# ADuCM320i register map
Vendor: Analog Devices Inc.; Series: ARMCM3; File version: 1.0
CPU: CM3 r2p1, little endian, no MPU, no FPU, 3 interrupt priority bits
Registers are 16-bit, read-write, no defined reset value unless marked. A register's access mark holds for its fields unless they carry their own. Offsets are from the block's base; [hi:lo] are bit positions.

## Timer1 — General purpose timer 1
Base 0x40000400
0x00 T1LD — 16-bit load value register
  [15:0] LOAD range 0x00000000..0x0000FFFF — Load value
0x04 T1VAL ro — 16-bit timer value register
  [15:0] VAL range 0x00000000..0x0000FFFF — Current count
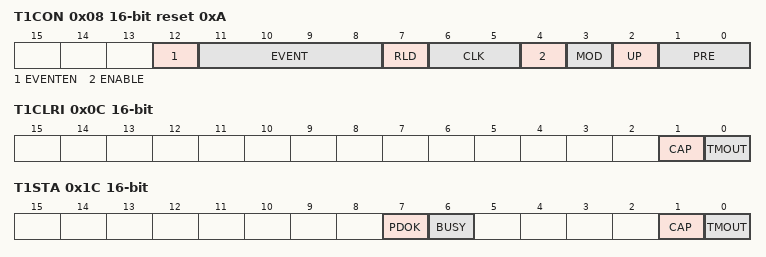
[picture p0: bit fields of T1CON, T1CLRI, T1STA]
0x08 T1CON reset 0xA (reset mask 0x0) — Control register
  [12] EVENTEN — Event select
    0=DIS (Events will not be captured); 1=EN (Events will be captured)
  [11:8] EVENT range 0x00000000..0x0000000F — Event select range
  [7] RLD — Reload control
    1=EN (Resets the up/down counter when TCLRI[0] is set); 0=DIS (Up/Down counter is only reset on a timeout event)
  [6:5] CLK — Clock select
    0=PCLK; 1=HCLK; 2=LFOSC (32 KHz OSC); 3=HFXTAL (16 MHz OSC or XTAL (Dependent on CLKCON0.11))
  [4] ENABLE — Timer enable
    0=DIS (Timer is disabled (default)); 1=EN (Timer is enabled)
  [3] MOD — Timer mode
    0=FREERUN (Timer runs in free running mode); 1=PERIODIC (Timer runs in periodic mode (default))
  [2] UP — Count up
    0=DIS (Timer is set to count down (default)); 1=EN (Timer is set to count up)
  [1:0] PRE — Prescaler
    0=DIV1 (source_clock / [1 or 4]); 1=DIV16 (source_clock / 16); 2=DIV256 (source_clock / 256); 3=DIV32768 (source_clock / 32,768)
0x0C T1CLRI wo — Clear interrupt register
  [1] CAP — Clear captured event interrupt
    1=CLR (Clear the capture event interrupt)
  [0] TMOUT — Clear timeout interrupt
    1=CLR (Clears the timeout interrupt)
0x10 T1CAP ro — Capture register
  [15:0] CAP range 0x00000000..0x0000FFFF — 16-bit captured value
0x1C T1STA ro — Status register
  [7] PDOK — TCLRI synchronization
    0=CLR (The interrupt is cleared in the timer clock domain); 1=SET (TCLRI[0] is being updated in the timer clock domain)
  [6] BUSY — Timer Busy
    0=CLR (Timer ready to receive commands to TCON); 1=SET (Timer not ready to receive commands to TCON)
  [1] CAP — Capture event pending
    0=CLR (No capture event is pending); 1=SET (A capture event is pending)
  [0] TMOUT — Timeout event occurred
    0=CLR (No timeout event has occurred); 1=SET (A timeout event has occurred)

## Timer2 — General purpose timer 2
Base 0x40000800
0x00 T2LD — 16-bit load value register
  [15:0] LOAD range 0x00000000..0x0000FFFF — Load value
0x04 T2VAL ro — 16-bit timer value register
  [15:0] VAL range 0x00000000..0x0000FFFF — Current count
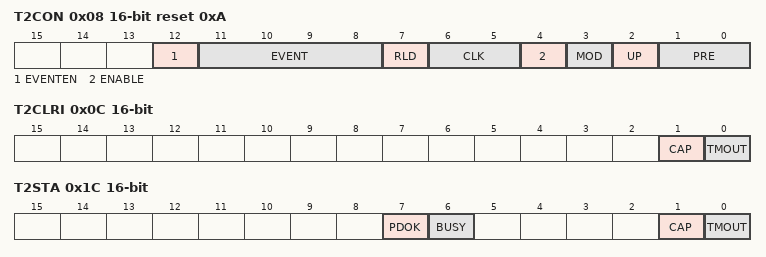
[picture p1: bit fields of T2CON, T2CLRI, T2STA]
0x08 T2CON reset 0xA (reset mask 0x0) — Control register
  [12] EVENTEN — Event select
    0=DIS (Events will not be captured); 1=EN (Events will be captured)
  [11:8] EVENT range 0x00000000..0x0000000F — Event select range
  [7] RLD — Reload control
    1=EN (Resets the up/down counter when TCLRI[0] is set); 0=DIS (Up/Down counter is only reset on a timeout event)
  [6:5] CLK — Clock select
    0=PCLK; 1=HCLK; 2=LFOSC (32 KHz OSC); 3=HFXTAL (16 MHz OSC or XTAL (Dependent on CLKCON0.11))
  [4] ENABLE — Timer enable
    0=DIS (Timer is disabled (default)); 1=EN (Timer is enabled)
  [3] MOD — Timer mode
    0=FREERUN (Timer runs in free running mode); 1=PERIODIC (Timer runs in periodic mode (default))
  [2] UP — Count up
    0=DIS (Timer is set to count down (default)); 1=EN (Timer is set to count up)
  [1:0] PRE — Prescaler
    0=DIV1 (source_clock / [1 or 4]); 1=DIV16 (source_clock / 16); 2=DIV256 (source_clock / 256); 3=DIV32768 (source_clock / 32,768)
0x0C T2CLRI wo — Clear interrupt register
  [1] CAP — Clear captured event interrupt
    1=CLR (Clear the capture event interrupt)
  [0] TMOUT — Clear timeout interrupt
    1=CLR (Clears the timeout interrupt)
0x10 T2CAP ro — Capture register
  [15:0] CAP range 0x00000000..0x0000FFFF — 16-bit captured value
0x1C T2STA ro — Status register
  [7] PDOK — TCLRI synchronization
    0=CLR (The interrupt is cleared in the timer clock domain); 1=SET (TCLRI[0] is being updated in the timer clock domain)
  [6] BUSY — Timer Busy
    0=CLR (Timer ready to receive commands to TCON); 1=SET (Timer not ready to receive commands to TCON)
  [1] CAP — Capture event pending
    0=CLR (No capture event is pending); 1=SET (A capture event is pending)
  [0] TMOUT — Timeout event occurred
    0=CLR (No timeout event has occurred); 1=SET (A timeout event has occurred)

## Notices in the file
Copyright (C) 2014 Analog Devices Inc. All rights reserved. Purpose:
System Viewer Description (SVD) Schema Version 1.1) for the ADuCM320i device.
